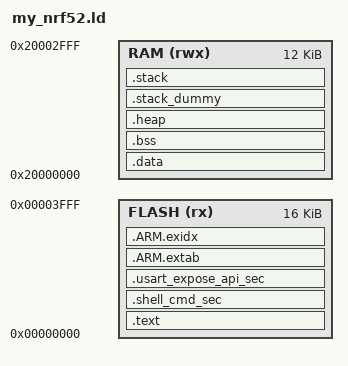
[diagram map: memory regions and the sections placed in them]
OUTPUT_FORMAT ("elf32-littlearm", "elf32-bigarm", "elf32-littlearm")

SEARCH_DIR(.)
GROUP(-lgcc -lc -lnosys)

ENTRY(Reset_Handler)

MEMORY
{
  FLASH (rx) : ORIGIN = 0x0, LENGTH = 0x04000
  RAM (rwx) :  ORIGIN = 0x20000000, LENGTH = 0x3000
}

SECTIONS
{
    .text :
    {
        KEEP(*(.isr_vector))
        *(.text*)

        KEEP(*(.init))
        KEEP(*(.fini))

        /* .ctors */
        *crtbegin.o(.ctors)
        *crtbegin?.o(.ctors)
        *(EXCLUDE_FILE(*crtend?.o *crtend.o) .ctors)
        *(SORT(.ctors.*))
        *(.ctors)

        /* .dtors */
        *crtbegin.o(.dtors)
        *crtbegin?.o(.dtors)
        *(EXCLUDE_FILE(*crtend?.o *crtend.o) .dtors)
        *(SORT(.dtors.*))
        *(.dtors)

        *(.rodata*)

        KEEP(*(.eh_frame*))
    } > FLASH

    .shell_cmd_sec :
    {
      . = ALIGN(4);
      __shell_cmd_sec_start__ = .;
      KEEP(*(shell_cmd_sec))
      __shell_cmd_sec_end__ = .;
    } > FLASH

    
    .usart_expose_api_sec :
    {
        . = ALIGN(16);
        __start_usart_expose_api = .;
        KEEP(*(usart_expose_api_sec))
    } > FLASH

    .ARM.extab :
    {
        *(.ARM.extab* .gnu.linkonce.armextab.*)
    } > FLASH

    __exidx_start = .;
    .ARM.exidx :
    {
        *(.ARM.exidx* .gnu.linkonce.armexidx.*)
    } > FLASH
    __exidx_end = .;

    . = ALIGN(4);
    __etext = .;

    .data : AT (__etext)
    {
        __data_start__ = .;
        *(vtable)
        *(.data*)

        . = ALIGN(4);
        /* preinit data */
        PROVIDE_HIDDEN (__preinit_array_start = .);
        KEEP(*(.preinit_array))
        PROVIDE_HIDDEN (__preinit_array_end = .);

        . = ALIGN(4);
        /* init data */
        PROVIDE_HIDDEN (__init_array_start = .);
        KEEP(*(SORT(.init_array.*)))
        KEEP(*(.init_array))
        PROVIDE_HIDDEN (__init_array_end = .);


        . = ALIGN(4);
        /* finit data */
        PROVIDE_HIDDEN (__fini_array_start = .);
        KEEP(*(SORT(.fini_array.*)))
        KEEP(*(.fini_array))
        PROVIDE_HIDDEN (__fini_array_end = .);

        KEEP(*(.jcr*))
        . = ALIGN(4);
        /* All data end */
        __data_end__ = .;

    } > RAM

    .bss :
    {
        . = ALIGN(4);
        __bss_start__ = .;
        *(.bss*)
        *(COMMON)
        . = ALIGN(4);
        __bss_end__ = .;
    } > RAM
    
    .heap (COPY):
    {
        __HeapBase = .;
        __end__ = .;
        PROVIDE(end = .);
        KEEP(*(.heap*))
        __HeapLimit = .;
    } > RAM

    /* .stack_dummy section doesn't contains any symbols. It is only
     * used for linker to calculate size of stack sections, and assign
     * values to stack symbols later */
    .stack_dummy (COPY):
    {
        KEEP(*(.stack*))
    } > RAM

    /* Set stack top to end of RAM, and stack limit move down by
     * size of stack_dummy section */
    __StackTop = ORIGIN(RAM) + LENGTH(RAM);
    __StackLimit = __StackTop - SIZEOF(.stack_dummy);
    PROVIDE(__stack = __StackTop);

     .stack (NOLOAD):
    {
        . = ALIGN(8);
        _sstack = .;
        . = . + 0x2000;
        . = ALIGN(8);
        _estack = .;
    } > RAM

    . = ALIGN(4);
    _end = . ;
}

